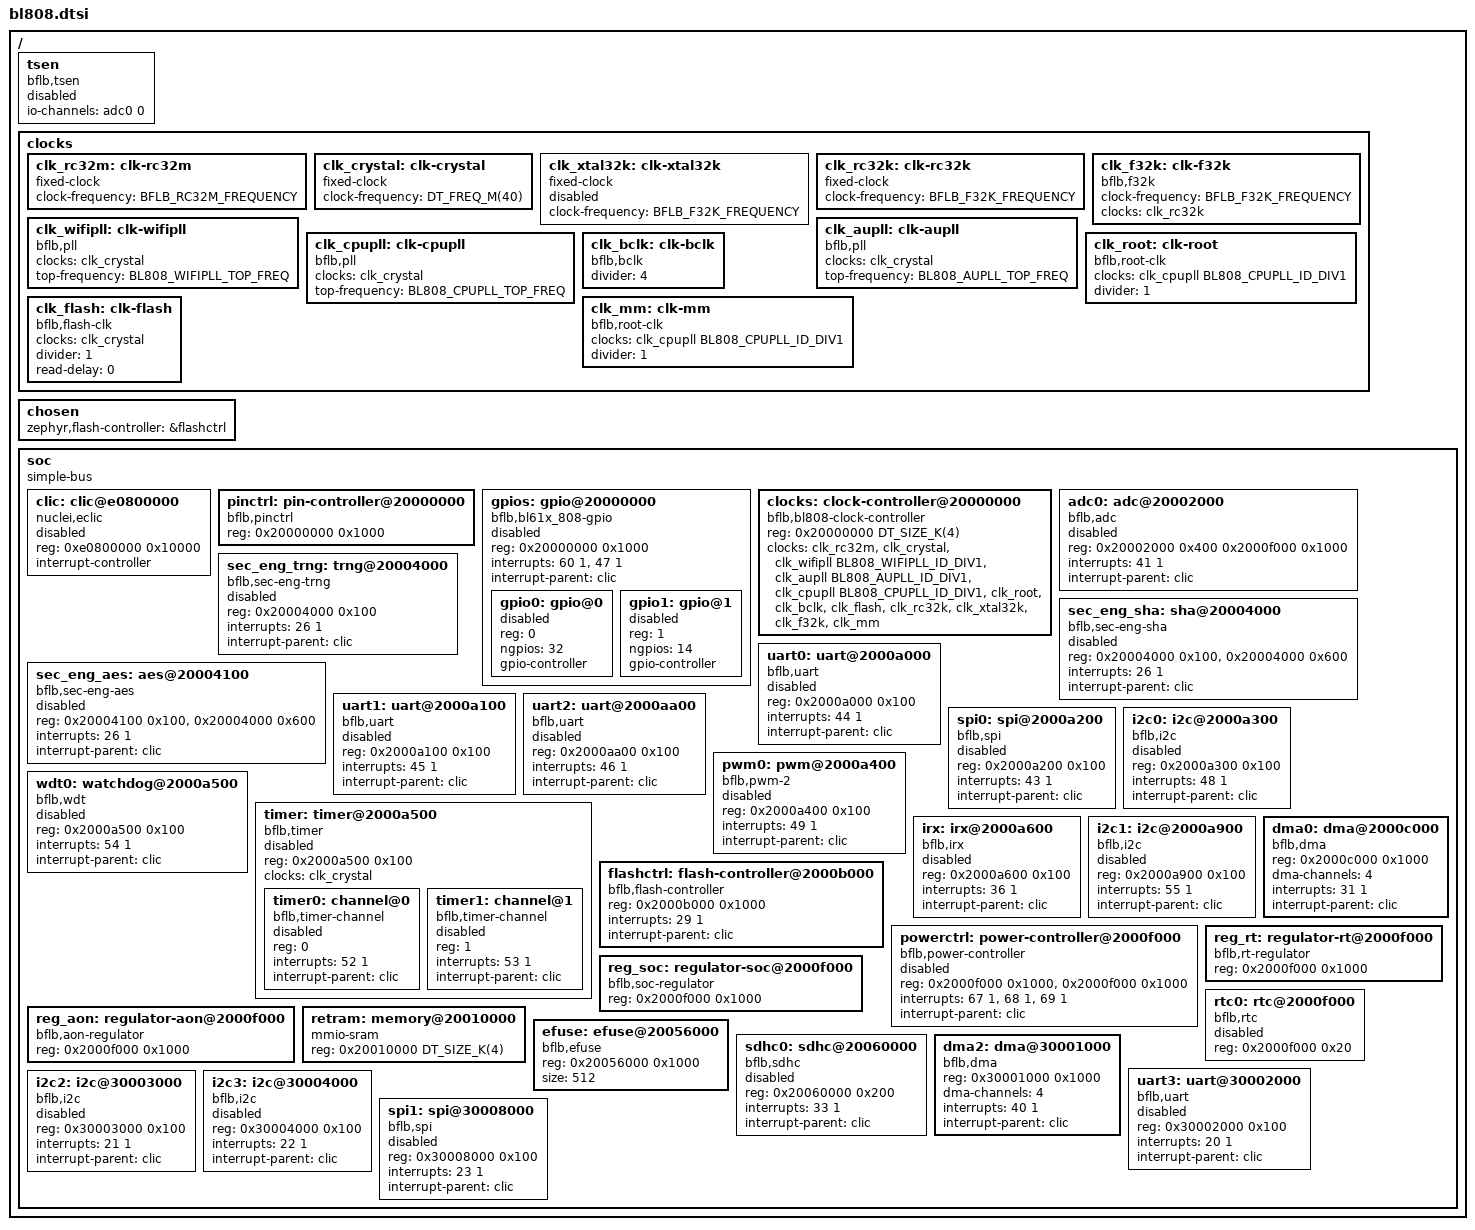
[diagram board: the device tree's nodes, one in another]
/*
 * Copyright The Zephyr Project Contributors
 *
 * SPDX-License-Identifier: Apache-2.0
 *
 * BL808 SoC devicetree — clocks, peripherals, and memory regions.
 * Per-core dtsi files add CPU, interrupt controller, timer, RAM,
 * and wire interrupt-parent to peripherals they use.
 */

#include <freq.h>
#include <mem.h>
#include <zephyr/dt-bindings/clock/bflb_bl808_clock.h>
#include <zephyr/dt-bindings/i2c/i2c.h>
#include <zephyr/dt-bindings/pinctrl/bflb-common-pinctrl.h>
#include <zephyr/dt-bindings/pinctrl/bl808x-pinctrl.h>
#include <zephyr/dt-bindings/gpio/gpio.h>

/ {
	#address-cells = <1>;
	#size-cells = <1>;

	tsen: tsen {
		compatible = "bflb,tsen";
		io-channels = <&adc0 0>;
		status = "disabled";
	};

	clocks {
		clk_rc32m: clk-rc32m {
			#clock-cells = <0>;
			compatible = "fixed-clock";
			clock-frequency = <BFLB_RC32M_FREQUENCY>;
			status = "okay";
		};

		clk_crystal: clk-crystal {
			#clock-cells = <0>;
			compatible = "fixed-clock";
			clock-frequency = <DT_FREQ_M(40)>;
			status = "okay";
		};

		clk_xtal32k: clk-xtal32k {
			#clock-cells = <0>;
			compatible = "fixed-clock";
			clock-frequency = <BFLB_F32K_FREQUENCY>;
			status = "disabled";
		};

		clk_rc32k: clk-rc32k {
			#clock-cells = <0>;
			compatible = "fixed-clock";
			clock-frequency = <BFLB_F32K_FREQUENCY>;
			status = "okay";
		};

		clk_f32k: clk-f32k {
			#clock-cells = <0>;
			compatible = "bflb,f32k";
			clock-frequency = <BFLB_F32K_FREQUENCY>;
			clocks = <&clk_rc32k>;
			status = "okay";
		};

		clk_wifipll: clk-wifipll {
			#clock-cells = <1>;
			compatible = "bflb,pll";
			clocks = <&clk_crystal>;
			top-frequency = <BL808_WIFIPLL_TOP_FREQ>;
			status = "okay";
		};

		clk_aupll: clk-aupll {
			#clock-cells = <1>;
			compatible = "bflb,pll";
			clocks = <&clk_crystal>;
			top-frequency = <BL808_AUPLL_TOP_FREQ>;
			status = "okay";
		};

		clk_cpupll: clk-cpupll {
			#clock-cells = <1>;
			compatible = "bflb,pll";
			clocks = <&clk_crystal>;
			top-frequency = <BL808_CPUPLL_TOP_FREQ>;
			status = "okay";
		};

		clk_root: clk-root {
			#clock-cells = <0>;
			compatible = "bflb,root-clk";
			clocks = <&clk_cpupll BL808_CPUPLL_ID_DIV1>;
			divider = <1>;
			status = "okay";
		};

		clk_bclk: clk-bclk {
			#clock-cells = <0>;
			compatible = "bflb,bclk";
			divider = <4>;
			status = "okay";
		};

		clk_flash: clk-flash {
			#clock-cells = <0>;
			compatible = "bflb,flash-clk";
			clocks = <&clk_crystal>;
			divider = <1>;
			read-delay = <0>;
			status = "okay";
		};

		clk_mm: clk-mm {
			#clock-cells = <0>;
			compatible = "bflb,root-clk";
			clocks = <&clk_cpupll BL808_CPUPLL_ID_DIV1>;
			divider = <1>;
			status = "okay";
		};
	};

	chosen {
		zephyr,flash-controller = &flashctrl;
	};

	soc: soc {
		compatible = "simple-bus";
		#address-cells = <1>;
		#size-cells = <1>;
		ranges;

		/* Default interrupt controller (M0/LP CLIC).
		 * D0 overrides this with PLIC for its peripherals.
		 */
		clic: clic@e0800000 {
			compatible = "nuclei,eclic";
			reg = <0xe0800000 0x10000>;
			#address-cells = <0>;
			#interrupt-cells = <2>;
			interrupt-controller;
			status = "disabled";
		};

		pinctrl: pin-controller@20000000 {
			compatible = "bflb,pinctrl";
			reg = <0x20000000 0x1000>;
			#address-cells = <1>;
			#size-cells = <1>;
			status = "okay";
		};

		gpios: gpio@20000000 {
			compatible = "bflb,bl61x_808-gpio";
			reg = <0x20000000 0x1000>;
			#address-cells = <1>;
			#size-cells = <0>;
			interrupts = <60 1>, <47 1>;
			interrupt-names = "gpio", "fifo";
			interrupt-parent = <&clic>;
			status = "disabled";

			gpio0: gpio@0 {
				#gpio-cells = <2>;
				reg = <0>;
				ngpios = <32>;
				status = "disabled";
				gpio-controller;
			};

			gpio1: gpio@1 {
				#gpio-cells = <2>;
				reg = <1>;
				ngpios = <14>;
				status = "disabled";
				gpio-controller;
			};
		};

		clocks: clock-controller@20000000 {
			compatible = "bflb,bl808-clock-controller", "bflb,clock-controller";
			reg = <0x20000000 DT_SIZE_K(4)>;
			#clock-cells = <1>;
			status = "okay";
			clocks = <&clk_rc32m>, <&clk_crystal>,
				 <&clk_wifipll BL808_WIFIPLL_ID_DIV1>,
				 <&clk_aupll BL808_AUPLL_ID_DIV1>,
				 <&clk_cpupll BL808_CPUPLL_ID_DIV1>,
				 <&clk_root>, <&clk_bclk>, <&clk_flash>,
				 <&clk_rc32k>, <&clk_xtal32k>, <&clk_f32k>,
				 <&clk_mm>;
			clock-names = "rc32m", "crystal",
				      "wifipll_top",
				      "aupll_top",
				      "cpupll_top",
				      "root", "bclk", "flash",
				      "rc32k", "xtal32k", "f32k",
				      "mm";
		};

		adc0: adc@20002000 {
			compatible = "bflb,adc";
			reg = <0x20002000 0x400 0x2000f000 0x1000>;
			#io-channel-cells = <1>;
			#address-cells = <1>;
			#size-cells = <0>;
			interrupts = <41 1>;
			interrupt-parent = <&clic>;
			status = "disabled";
		};

		sec_eng_trng: trng@20004000 {
			compatible = "bflb,sec-eng-trng";
			reg = <0x20004000 0x100>;
			interrupts = <26 1>;
			interrupt-parent = <&clic>;
			status = "disabled";
		};

		sec_eng_sha: sha@20004000 {
			compatible = "bflb,sec-eng-sha";
			reg = <0x20004000 0x100>, <0x20004000 0x600>;
			reg-names = "sha", "sec_eng";
			interrupts = <26 1>;
			interrupt-parent = <&clic>;
			status = "disabled";
		};

		sec_eng_aes: aes@20004100 {
			compatible = "bflb,sec-eng-aes";
			reg = <0x20004100 0x100>, <0x20004000 0x600>;
			reg-names = "aes", "sec_eng";
			interrupts = <26 1>;
			interrupt-parent = <&clic>;
			status = "disabled";
		};

		uart0: uart@2000a000 {
			compatible = "bflb,uart";
			reg = <0x2000a000 0x100>;
			interrupts = <44 1>;
			interrupt-parent = <&clic>;
			status = "disabled";
		};

		uart1: uart@2000a100 {
			compatible = "bflb,uart";
			reg = <0x2000a100 0x100>;
			interrupts = <45 1>;
			interrupt-parent = <&clic>;
			status = "disabled";
		};

		uart2: uart@2000aa00 {
			compatible = "bflb,uart";
			reg = <0x2000aa00 0x100>;
			interrupts = <46 1>;
			interrupt-parent = <&clic>;
			status = "disabled";
		};

		spi0: spi@2000a200 {
			compatible = "bflb,spi";
			reg = <0x2000a200 0x100>;
			#address-cells = <1>;
			#size-cells = <0>;
			interrupts = <43 1>;
			interrupt-parent = <&clic>;
			status = "disabled";
		};

		i2c0: i2c@2000a300 {
			compatible = "bflb,i2c";
			reg = <0x2000a300 0x100>;
			#address-cells = <1>;
			#size-cells = <0>;
			interrupts = <48 1>;
			interrupt-parent = <&clic>;
			status = "disabled";
		};

		pwm0: pwm@2000a400 {
			compatible = "bflb,pwm-2";
			reg = <0x2000a400 0x100>;
			#pwm-cells = <3>;
			interrupts = <49 1>;
			interrupt-parent = <&clic>;
			status = "disabled";
		};

		wdt0: watchdog@2000a500 {
			compatible = "bflb,wdt";
			reg = <0x2000a500 0x100>;
			interrupts = <54 1>;
			interrupt-parent = <&clic>;
			status = "disabled";
		};

		timer: timer@2000a500 {
			compatible = "bflb,timer";
			reg = <0x2000a500 0x100>;
			clocks = <&clk_crystal>;
			#address-cells = <1>;
			#size-cells = <0>;
			status = "disabled";

			timer0: channel@0 {
				compatible = "bflb,timer-channel";
				reg = <0>;
				interrupts = <52 1>;
				interrupt-parent = <&clic>;
				status = "disabled";
			};

			timer1: channel@1 {
				compatible = "bflb,timer-channel";
				reg = <1>;
				interrupts = <53 1>;
				interrupt-parent = <&clic>;
				status = "disabled";
			};
		};

		irx: irx@2000a600 {
			compatible = "bflb,irx";
			reg = <0x2000a600 0x100>;
			#address-cells = <1>;
			#size-cells = <0>;
			interrupts = <36 1>;
			interrupt-parent = <&clic>;
			status = "disabled";
		};

		i2c1: i2c@2000a900 {
			compatible = "bflb,i2c";
			reg = <0x2000a900 0x100>;
			#address-cells = <1>;
			#size-cells = <0>;
			interrupts = <55 1>;
			interrupt-parent = <&clic>;
			status = "disabled";
		};

		flashctrl: flash-controller@2000b000 {
			compatible = "bflb,flash-controller";
			reg = <0x2000b000 0x1000>;
			#address-cells = <1>;
			#size-cells = <1>;
			interrupts = <29 1>;
			interrupt-parent = <&clic>;
			status = "okay";
		};

		dma0: dma@2000c000 {
			compatible = "bflb,dma";
			reg = <0x2000c000 0x1000>;
			#dma-cells = <2>;
			dma-channels = <4>;
			interrupts = <31 1>;
			interrupt-parent = <&clic>;
		};

		powerctrl: power-controller@2000f000 {
			compatible = "bflb,power-controller";
			reg = <0x2000f000 0x1000>, <0x2000f000 0x1000>;
			reg-names = "hbn", "aon";
			interrupts = <67 1>, <68 1>, <69 1>;
			interrupt-parent = <&clic>;
			interrupt-names = "hbn0", "hbn1", "bor";
			status = "disabled";
		};

		reg_soc: regulator-soc@2000f000 {
			compatible = "bflb,soc-regulator";
			reg = <0x2000f000 0x1000>;
			status = "okay";
		};

		reg_rt: regulator-rt@2000f000 {
			compatible = "bflb,rt-regulator";
			reg = <0x2000f000 0x1000>;
			status = "okay";
		};

		reg_aon: regulator-aon@2000f000 {
			compatible = "bflb,aon-regulator";
			reg = <0x2000f000 0x1000>;
			status = "okay";
		};

		rtc0: rtc@2000f000 {
			compatible = "bflb,rtc";
			reg = <0x2000f000 0x20>;
			status = "disabled";
		};

		retram: memory@20010000 {
			compatible = "mmio-sram";
			reg = <0x20010000 DT_SIZE_K(4)>;
		};

		efuse: efuse@20056000 {
			compatible = "bflb,efuse";
			reg = <0x20056000 0x1000>;
			status = "okay";
			size = <512>;
		};

		sdhc0: sdhc@20060000 {
			compatible = "bflb,sdhc";
			reg = <0x20060000 0x200>;
			interrupts = <33 1>;
			interrupt-parent = <&clic>;
			status = "disabled";
		};

		/* MM-domain peripherals (D0 subsystem) */
		dma2: dma@30001000 {
			compatible = "bflb,dma";
			reg = <0x30001000 0x1000>;
			#dma-cells = <2>;
			dma-channels = <4>;
			interrupts = <40 1>;
			interrupt-parent = <&clic>;
		};

		uart3: uart@30002000 {
			compatible = "bflb,uart";
			reg = <0x30002000 0x100>;
			interrupts = <20 1>;
			interrupt-parent = <&clic>;
			status = "disabled";
		};

		i2c2: i2c@30003000 {
			compatible = "bflb,i2c";
			reg = <0x30003000 0x100>;
			#address-cells = <1>;
			#size-cells = <0>;
			interrupts = <21 1>;
			interrupt-parent = <&clic>;
			status = "disabled";
		};

		i2c3: i2c@30004000 {
			compatible = "bflb,i2c";
			reg = <0x30004000 0x100>;
			#address-cells = <1>;
			#size-cells = <0>;
			interrupts = <22 1>;
			interrupt-parent = <&clic>;
			status = "disabled";
		};

		spi1: spi@30008000 {
			compatible = "bflb,spi";
			reg = <0x30008000 0x100>;
			#address-cells = <1>;
			#size-cells = <0>;
			interrupts = <23 1>;
			interrupt-parent = <&clic>;
			status = "disabled";
		};
	};
};
